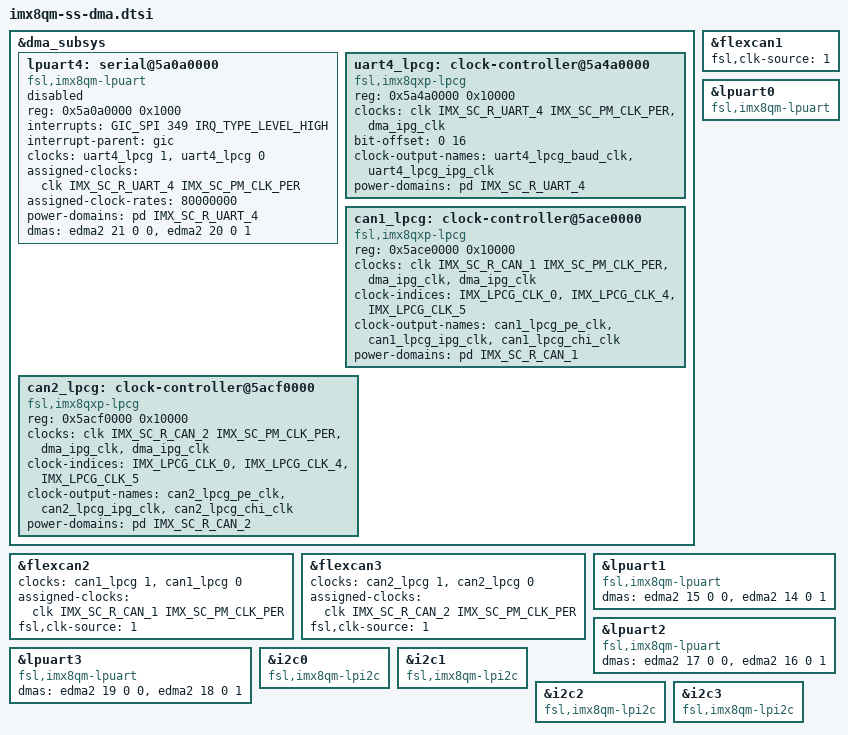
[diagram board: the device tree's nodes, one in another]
// SPDX-License-Identifier: GPL-2.0+
/*
 * Copyright 2018-2019 NXP
 *	Dong Aisheng <aisheng.dong@nxp.com>
 */

&dma_subsys {
	lpuart4: serial@5a0a0000 {
		compatible = "fsl,imx8qm-lpuart", "fsl,imx8qxp-lpuart";
		reg = <0x5a0a0000 0x1000>;
		interrupts = <GIC_SPI 349 IRQ_TYPE_LEVEL_HIGH>;
		interrupt-parent = <&gic>;
		clocks = <&uart4_lpcg 1>, <&uart4_lpcg 0>;
		clock-names = "ipg", "baud";
		assigned-clocks = <&clk IMX_SC_R_UART_4 IMX_SC_PM_CLK_PER>;
		assigned-clock-rates = <80000000>;
		power-domains = <&pd IMX_SC_R_UART_4>;
		power-domain-names = "uart";
		dma-names = "tx","rx";
		dmas = <&edma2 21 0 0>,
		       <&edma2 20 0 1>;
		status = "disabled";
	};

	uart4_lpcg: clock-controller@5a4a0000 {
		compatible = "fsl,imx8qxp-lpcg";
		reg = <0x5a4a0000 0x10000>;
		#clock-cells = <1>;
		clocks = <&clk IMX_SC_R_UART_4 IMX_SC_PM_CLK_PER>,
			 <&dma_ipg_clk>;
		bit-offset = <0 16>;
		clock-output-names = "uart4_lpcg_baud_clk",
				     "uart4_lpcg_ipg_clk";
		power-domains = <&pd IMX_SC_R_UART_4>;
	};

	can1_lpcg: clock-controller@5ace0000 {
		compatible = "fsl,imx8qxp-lpcg";
		reg = <0x5ace0000 0x10000>;
		#clock-cells = <1>;
		clocks = <&clk IMX_SC_R_CAN_1 IMX_SC_PM_CLK_PER>,
			 <&dma_ipg_clk>, <&dma_ipg_clk>;
		clock-indices = <IMX_LPCG_CLK_0>, <IMX_LPCG_CLK_4>, <IMX_LPCG_CLK_5>;
		clock-output-names = "can1_lpcg_pe_clk",
				     "can1_lpcg_ipg_clk",
				     "can1_lpcg_chi_clk";
		power-domains = <&pd IMX_SC_R_CAN_1>;
	};

	can2_lpcg: clock-controller@5acf0000 {
		compatible = "fsl,imx8qxp-lpcg";
		reg = <0x5acf0000 0x10000>;
		#clock-cells = <1>;
		clocks = <&clk IMX_SC_R_CAN_2 IMX_SC_PM_CLK_PER>,
			 <&dma_ipg_clk>, <&dma_ipg_clk>;
		clock-indices = <IMX_LPCG_CLK_0>, <IMX_LPCG_CLK_4>, <IMX_LPCG_CLK_5>;
		clock-output-names = "can2_lpcg_pe_clk",
				     "can2_lpcg_ipg_clk",
				     "can2_lpcg_chi_clk";
		power-domains = <&pd IMX_SC_R_CAN_2>;
	};
};

&flexcan1 {
	fsl,clk-source = /bits/ 8 <1>;
};

&flexcan2 {
	clocks = <&can1_lpcg 1>,
		 <&can1_lpcg 0>;
	assigned-clocks = <&clk IMX_SC_R_CAN_1 IMX_SC_PM_CLK_PER>;
	fsl,clk-source = /bits/ 8 <1>;
};

&flexcan3 {
	clocks = <&can2_lpcg 1>,
		 <&can2_lpcg 0>;
	assigned-clocks = <&clk IMX_SC_R_CAN_2 IMX_SC_PM_CLK_PER>;
	fsl,clk-source = /bits/ 8 <1>;
};

&lpuart0 {
	compatible = "fsl,imx8qm-lpuart", "fsl,imx8qxp-lpuart";
};

&lpuart1 {
	compatible = "fsl,imx8qm-lpuart", "fsl,imx8qxp-lpuart";
	dmas = <&edma2 15 0 0>,
	       <&edma2 14 0 1>;
};

&lpuart2 {
	compatible = "fsl,imx8qm-lpuart", "fsl,imx8qxp-lpuart";
	dmas = <&edma2 17 0 0>,
	       <&edma2 16 0 1>;
};

&lpuart3 {
	compatible = "fsl,imx8qm-lpuart", "fsl,imx8qxp-lpuart";
	dmas = <&edma2 19 0 0>,
	       <&edma2 18 0 1>;
};

&i2c0 {
	compatible = "fsl,imx8qm-lpi2c", "fsl,imx7ulp-lpi2c";
};

&i2c1 {
	compatible = "fsl,imx8qm-lpi2c", "fsl,imx7ulp-lpi2c";
};

&i2c2 {
	compatible = "fsl,imx8qm-lpi2c", "fsl,imx7ulp-lpi2c";
};

&i2c3 {
	compatible = "fsl,imx8qm-lpi2c", "fsl,imx7ulp-lpi2c";
};
